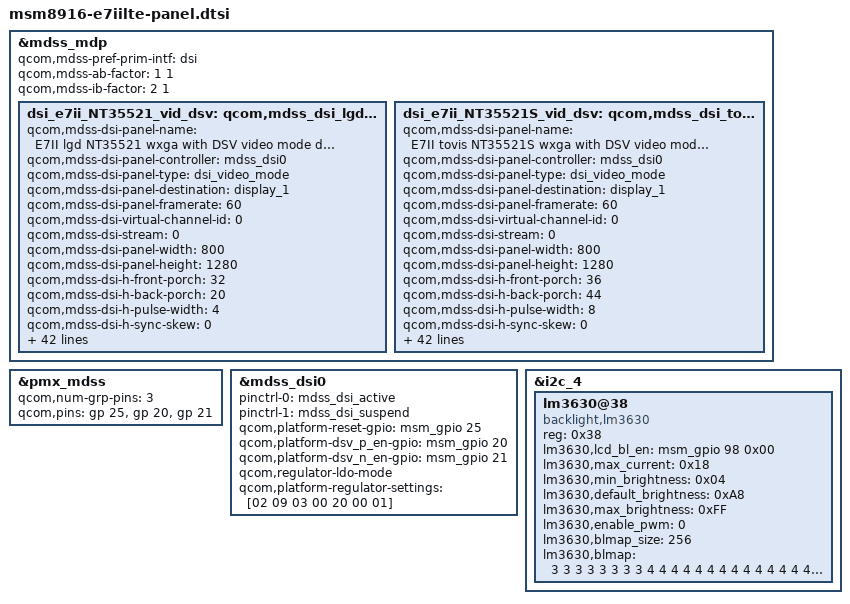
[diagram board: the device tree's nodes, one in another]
/* Copyright (c) 2013, Code Aurora Forum. All rights reserved.
 *
 * This program is free software; you can redistribute it and/or modify
 * it under the terms of the GNU General Public License version 2 and
 * only version 2 as published by the Free Software Foundation.
 *
 * This program is distributed in the hope that it will be useful,
 * but WITHOUT ANY WARRANTY; without even the implied warranty of
 * MERCHANTABILITY or FITNESS FOR A PARTICULAR PURPOSE.  See the
 * GNU General Public License for more details.
 */

&mdss_mdp {
	dsi_e7ii_NT35521_vid_dsv: qcom,mdss_dsi_lgd_nt35521_e7II_wxga_video {
		qcom,mdss-dsi-panel-name = "E7II lgd NT35521 wxga with DSV video mode dsi primary panel";
		qcom,mdss-dsi-panel-controller = <&mdss_dsi0>;
		qcom,mdss-dsi-panel-type = "dsi_video_mode";
		qcom,mdss-dsi-panel-destination = "display_1";
		qcom,mdss-dsi-panel-framerate = <60>;
		qcom,mdss-dsi-virtual-channel-id = <0>;
		qcom,mdss-dsi-stream = <0>;
		qcom,mdss-dsi-panel-width = <800>;
		qcom,mdss-dsi-panel-height = <1280>;
		qcom,mdss-dsi-h-front-porch = <32>;
		qcom,mdss-dsi-h-back-porch = <20>;
		qcom,mdss-dsi-h-pulse-width = <4>;
		qcom,mdss-dsi-h-sync-skew = <0>;
		qcom,mdss-dsi-v-front-porch = <32>;
		qcom,mdss-dsi-v-back-porch = <20>;
		qcom,mdss-dsi-v-pulse-width = <4>;
		qcom,mdss-dsi-h-left-border = <0>;
		qcom,mdss-dsi-h-right-border = <0>;
		qcom,mdss-dsi-v-top-border = <0>;
		qcom,mdss-dsi-v-bottom-border = <0>;
		qcom,mdss-pan-physical-width-dimension = < 94 >;
		qcom,mdss-pan-physical-height-dimension = < 150 >;
		qcom,mdss-dsi-bpp = <24>;
		qcom,mdss-dsi-color-order = "rgb_swap_rgb";
		qcom,mdss-dsi-underflow-color = <0x0>;
		qcom,mdss-dsi-border-color = <0>;
		qcom,mdss-dsi-lp11-init;
		qcom,cont-splash-enabled;
		qcom,mdss-dsi-on-command = [
		39 01 00 00 00 00 05 FF AA 55 A5 80
		15 01 00 00 00 00 02 6F 02
		15 01 00 00 00 00 02 F7 47
		15 01 00 00 00 00 02 6F 17
		15 01 00 00 00 00 02 F4 60
		39 01 00 00 00 00 06 F0 55 AA 52 08 00
		39 01 00 00 00 00 03 B1 28 01
		15 01 00 00 00 00 02 B5 C8
		15 01 00 00 00 00 02 B6 0A
		39 01 00 00 00 00 05 B8 01 02 0C 02
		39 01 00 00 00 00 03 BB 33 33
		39 01 00 00 00 00 03 BC 05 05
		39 01 00 00 00 00 06 BD 02 67 20 20 00
		15 01 00 00 00 00 02 D0 00
		15 01 00 00 00 00 02 C8 83
		39 01 00 00 00 00 11 CC 40 36 87 00 00 00 00 00 00 00 00 00 40 08 A5 05
		39 01 00 00 00 00 11 D1 00 06 0A 0E 12 16 22 28 22 20 16 14 12 0E 08 00
		39 01 00 00 00 00 0D D7 26 28 25 23 23 00 00 00 00 00 00 00
		39 01 00 00 00 00 0E D8 00 00 00 00 00 00 00 00 00 00 23 25 00
		39 01 00 00 00 00 06 F0 55 AA 52 08 01
		39 01 00 00 00 00 03 B3 28 28
		39 01 00 00 00 00 03 B4 0F 0F
		39 01 00 00 00 00 03 B9 34 34
		39 01 00 00 00 00 03 BA 14 14
		39 01 00 00 00 00 03 BC 50 00
		39 01 00 00 00 00 03 BD 50 00
		15 01 00 00 00 00 02 C1 01
		15 01 00 00 00 00 02 CA 80
		39 01 00 00 00 00 03 CB 92 F4
		39 01 00 00 00 00 04 CD 15 03 01
		39 01 00 00 00 00 04 CF 00 50 50
		39 01 00 00 00 00 03 D0 50 50
		39 01 00 00 00 00 03 D1 50 50
		15 01 00 00 00 00 02 D2 39
		15 01 00 00 00 00 02 D3 39
		39 01 00 00 00 00 06 F0 55 AA 52 08 02
		15 01 00 00 00 00 02 EE 01
		39 01 00 00 00 00 11 B0 00 00 00 1E 00 48 00 68 00 81 00 AA 00 CA 00 FE
		39 01 00 00 00 00 11 B1 01 28 01 69 01 9C 01 EB 02 28 02 2A 02 61 02 9B
		39 01 00 00 00 00 11 B2 02 C2 02 F4 03 16 03 42 03 63 03 86 03 9F 03 BB
		39 01 00 00 00 00 05 B3 03 E6 03 FF
		39 01 00 00 00 00 06 F0 55 AA 52 08 03
		39 01 00 00 00 00 03 B0 22 00
		39 01 00 00 00 00 03 B1 22 00
		39 01 00 00 00 00 06 B2 05 00 B0 00 00
		39 01 00 00 00 00 06 B3 05 00 B0 00 00
		39 01 00 00 00 00 06 B4 05 00 B0 00 00
		39 01 00 00 00 00 06 B5 05 00 B0 00 00
		39 01 00 00 00 00 06 BA 53 00 B0 00 00
		39 01 00 00 00 00 06 BB 53 00 B0 00 00
		39 01 00 00 00 00 06 BC 53 00 B0 00 00
		39 01 00 00 00 00 06 BD 53 00 B0 00 00
		39 01 00 00 00 00 05 C0 00 60 00 00
		39 01 00 00 00 00 05 C1 00 00 60 00
		39 01 00 00 00 00 05 C2 00 00 34 00
		39 01 00 00 00 00 05 C3 00 00 34 00
		15 01 00 00 00 00 02 C4 60
		15 01 00 00 00 00 02 C5 C0
		15 01 00 00 00 00 02 C6 00
		15 01 00 00 00 00 02 C7 00
		39 01 00 00 00 00 06 F0 55 AA 52 08 05
		39 01 00 00 00 00 03 B0 17 06
		39 01 00 00 00 00 03 B1 17 06
		39 01 00 00 00 00 03 B2 17 06
		39 01 00 00 00 00 03 B3 17 06
		39 01 00 00 00 00 03 B4 17 06
		39 01 00 00 00 00 03 B5 17 06
		39 01 00 00 00 00 03 B6 17 06
		39 01 00 00 00 00 03 B7 17 06
		15 01 00 00 00 00 02 B8 00
		39 01 00 00 00 00 03 B9 00 03
		39 01 00 00 00 00 03 BA 00 00
		39 01 00 00 00 00 03 BB 02 03
		39 01 00 00 00 00 03 BC 02 03
		39 01 00 00 00 00 06 BD 03 03 00 03 03
		15 01 00 00 00 00 02 C0 0B
		15 01 00 00 00 00 02 C1 09
		15 01 00 00 00 00 02 C2 A6
		15 01 00 00 00 00 02 C3 05
		15 01 00 00 00 00 02 C4 00
		15 01 00 00 00 00 02 C5 02
		15 01 00 00 00 00 02 C6 22
		15 01 00 00 00 00 02 C7 03
		39 01 00 00 00 00 03 C8 07 20
		39 01 00 00 00 00 03 C9 03 20
		39 01 00 00 00 00 03 CA 01 60
		39 01 00 00 00 00 03 CB 01 60
		39 01 00 00 00 00 04 CC 00 00 78
		39 01 00 00 00 00 04 CD 00 00 78
		39 01 00 00 00 00 04 CE 00 00 02
		39 01 00 00 00 00 04 CF 00 00 02
		39 01 00 00 00 00 06 D1 00 05 01 07 10
		39 01 00 00 00 00 06 D2 10 05 05 03 10
		39 01 00 00 00 00 06 D3 20 00 43 07 10
		39 01 00 00 00 00 06 D4 30 00 43 07 10
		39 01 00 00 00 00 08 D0 00 00 00 00 00 00 00
		39 01 00 00 00 00 0C D5 00 00 00 00 00 00 00 00 00 00 00
		39 01 00 00 00 00 0C D6 00 00 00 00 00 00 00 00 00 00 00
		39 01 00 00 00 00 0C D7 00 00 00 00 00 00 00 00 00 00 00
		39 01 00 00 00 00 06 D8 00 00 00 00 00
		15 01 00 00 00 00 02 E5 06
		15 01 00 00 00 00 02 E6 06
		15 01 00 00 00 00 02 E7 00
		15 01 00 00 00 00 02 E8 06
		15 01 00 00 00 00 02 E9 06
		15 01 00 00 00 00 02 EA 06
		15 01 00 00 00 00 02 EB 00
		15 01 00 00 00 00 02 EC 00
		15 01 00 00 00 00 02 ED 30
		39 01 00 00 00 00 06 F0 55 AA 52 08 06
		39 01 00 00 00 00 03 B0 34 34
		39 01 00 00 00 00 03 B1 34 34
		39 01 00 00 00 00 03 B2 2D 2E
		39 01 00 00 00 00 03 B3 34 34
		39 01 00 00 00 00 03 B4 29 2A
		39 01 00 00 00 00 03 B5 13 11
		39 01 00 00 00 00 03 B6 19 17
		39 01 00 00 00 00 03 B7 01 03
		39 01 00 00 00 00 03 B8 34 31
		39 01 00 00 00 00 03 B9 31 31
		39 01 00 00 00 00 03 BA 31 31
		39 01 00 00 00 00 03 BB 31 34
		39 01 00 00 00 00 03 BC 02 00
		39 01 00 00 00 00 03 BD 16 18
		39 01 00 00 00 00 03 BE 10 12
		39 01 00 00 00 00 03 BF 2A 29
		39 01 00 00 00 00 03 C0 34 34
		39 01 00 00 00 00 03 C1 2E 2D
		39 01 00 00 00 00 03 C2 34 34
		39 01 00 00 00 00 03 C3 34 34
		39 01 00 00 00 00 06 D8 00 00 00 00 00
		39 01 00 00 00 00 06 D9 00 00 00 00 00
		39 01 00 00 00 00 05 FF AA 55 A5 00
		39 01 00 00 00 00 06 F0 55 AA 52 00 00
		05 01 00 00 78 00 02 11 00
		15 01 00 00 00 00 02 51 FF
		15 01 00 00 00 00 02 53 24
		15 01 00 00 00 00 02 55 80
		05 01 00 00 00 00 02 29 00];
		qcom,mdss-dsi-off-command = [
		05 01 00 00 32 00 02 28 00
		05 01 00 00 78 00 02 10 00
		];
		qcom,mdss-dsi-on-command-state = "dsi_lp_mode";
		qcom,mdss-dsi-off-command-state = "dsi_hs_mode";
		qcom,mdss-dsi-h-sync-pulse = <0>;
		qcom,mdss-dsi-traffic-mode = "non_burst_sync_event";
		qcom,mdss-dsi-lane-map = "lane_map_0123";
		qcom,mdss-dsi-bllp-eof-power-mode;
		qcom,mdss-dsi-bllp-power-mode;
		qcom,mdss-dsi-lane-0-state;
		qcom,mdss-dsi-lane-1-state;
		qcom,mdss-dsi-lane-2-state;
		qcom,mdss-dsi-lane-3-state;
		qcom,mdss-dsi-panel-timings = [7B 1A 10 00 3E 42 14 1C 15 03 04 00];
		qcom,mdss-dsi-t-clk-post = <0x04>;
		qcom,mdss-dsi-t-clk-pre = <0x1A>;
		qcom,mdss-dsi-bl-min-level = <1>;
		qcom,mdss-dsi-bl-max-level = <255>;
		qcom,mdss-dsi-dma-trigger = "trigger_sw";
		qcom,mdss-dsi-mdp-trigger = "none";
		qcom,mdss-dsi-bl-pmic-control-type = "bl_ctrl_wled";
		qcom,mdss-dsi-reset-sequence = <1 1>, <0 1>, <1 150>;
	};

	dsi_e7ii_NT35521S_vid_dsv: qcom,mdss_dsi_tovis_nt35521s_e7II_wxga_video {
		qcom,mdss-dsi-panel-name = "E7II tovis NT35521S wxga with DSV video mode dsi secondary panel";
		qcom,mdss-dsi-panel-controller = <&mdss_dsi0>;
		qcom,mdss-dsi-panel-type = "dsi_video_mode";
		qcom,mdss-dsi-panel-destination = "display_1";
		qcom,mdss-dsi-panel-framerate = <60>;
		qcom,mdss-dsi-virtual-channel-id = <0>;
		qcom,mdss-dsi-stream = <0>;
		qcom,mdss-dsi-panel-width = <800>;
		qcom,mdss-dsi-panel-height = <1280>;
		qcom,mdss-dsi-h-front-porch = <36>;
		qcom,mdss-dsi-h-back-porch = <44>;
		qcom,mdss-dsi-h-pulse-width = <8>;
		qcom,mdss-dsi-h-sync-skew = <0>;
		qcom,mdss-dsi-v-front-porch = <20>;
		qcom,mdss-dsi-v-back-porch = <36>;
		qcom,mdss-dsi-v-pulse-width = <2>;
		qcom,mdss-dsi-h-left-border = <0>;
		qcom,mdss-dsi-h-right-border = <0>;
		qcom,mdss-dsi-v-top-border = <0>;
		qcom,mdss-dsi-v-bottom-border = <0>;
		qcom,mdss-pan-physical-width-dimension = < 94 >;
		qcom,mdss-pan-physical-height-dimension = < 150 >;
		qcom,mdss-dsi-bpp = <24>;
		qcom,mdss-dsi-color-order = "rgb_swap_rgb";
		qcom,mdss-dsi-underflow-color = <0x0>;
		qcom,mdss-dsi-border-color = <0>;
		qcom,mdss-dsi-lp11-init;
		qcom,cont-splash-enabled;
		qcom,mdss-dsi-on-command = [
		39 01 00 00 00 00 06 F0 55 AA 52 08 00
		39 01 00 00 00 00 03 B1 68 01
		15 01 00 00 00 00 02 B6 01
		39 01 00 00 00 00 05 B8 01 02 02 02
		39 01 00 00 00 00 03 BB CC CC
		39 01 00 00 00 00 03 BC 05 05
		39 01 00 00 00 00 06 BD 01 A0 0C 08 01
		39 01 00 00 00 00 06 F0 55 AA 52 08 01
		39 01 00 00 00 00 03 B3 28 28
		39 01 00 00 00 00 03 B4 0F 0F
		39 01 00 00 00 00 03 B5 03 03
		39 01 00 00 00 00 03 B9 34 34
		39 01 00 00 00 00 03 BA 15 15
		39 01 00 00 00 00 03 BC 78 00
		39 01 00 00 00 00 03 BD 78 00
		15 01 00 00 00 00 02 CA 00
		39 01 00 00 00 00 06 F0 55 AA 52 08 02
		15 01 00 00 00 00 02 EE 02
		39 01 00 00 00 00 11 B0 00 64 00 7D 00 AE 00 C7 00 DF 01 04 01 23 01 52
		39 01 00 00 00 00 11 B1 01 74 01 B0 01 DF 02 27 02 62 02 64 02 97 02 CF
		39 01 00 00 00 00 11 B2 02 F0 03 1F 03 3E 03 63 03 7F 03 9F 03 B9 03 D4
		39 01 00 00 00 00 05 B3 03 EC 03 F0
		39 01 00 00 00 00 11 BC 00 64 00 7D 00 AE 00 C7 00 DF 01 04 01 23 01 52
		39 01 00 00 00 00 11 BD 01 74 01 B0 01 DF 02 27 02 62 02 64 02 97 02 CF
		39 01 00 00 00 00 11 BE 02 F0 03 1F 03 3E 03 63 03 7F 03 9F 03 B9 03 D4
		39 01 00 00 00 00 05 BF 03 EC 03 F0
		39 01 00 00 00 00 06 F0 55 AA 52 08 03
		39 01 00 00 00 00 03 B0 20 00
		39 01 00 00 00 00 03 B1 00 00
		39 01 00 00 00 00 06 B2 05 00 00 00 90
		39 01 00 00 00 00 06 B3 05 00 00 00 90
		39 01 00 00 00 00 06 B4 05 00 00 00 90
		39 01 00 00 00 00 06 B5 05 00 00 00 90
		39 01 00 00 00 00 06 B6 05 00 00 00 90
		39 01 00 00 00 00 06 B7 05 00 00 00 90
		39 01 00 00 00 00 06 B8 05 00 00 00 90
		39 01 00 00 00 00 06 B9 05 00 00 00 90
		39 01 00 00 00 00 06 BA 44 00 00 01 00
		39 01 00 00 00 00 06 BB 44 00 00 01 00
		39 01 00 00 00 00 06 BC 44 00 00 01 00
		39 01 00 00 00 00 06 BD 44 00 00 01 00
		15 01 00 00 00 00 02 C4 60
		15 01 00 00 00 00 02 C5 40
		15 01 00 00 00 00 02 C6 60
		15 01 00 00 00 00 02 C7 40
		39 01 00 00 00 00 06 F0 55 AA 52 08 05
		39 01 00 00 00 00 03 B0 17 06
		15 01 00 00 00 00 02 B8 00
		39 01 00 00 00 00 06 BD 03 03 01 00 03
		39 01 00 00 00 00 03 B1 17 06
		39 01 00 00 00 00 03 B9 00 03
		39 01 00 00 00 00 03 B2 17 06
		39 01 00 00 00 00 03 BA 00 00
		39 01 00 00 00 00 03 B3 17 06
		39 01 00 00 00 00 03 BB 00 00
		39 01 00 00 00 00 03 B4 17 06
		39 01 00 00 00 00 03 B5 17 06
		39 01 00 00 00 00 03 B6 17 06
		39 01 00 00 00 00 03 B7 17 06
		39 01 00 00 00 00 03 BC 00 03
		15 01 00 00 00 00 02 C0 0B
		15 01 00 00 00 00 02 C1 09
		15 01 00 00 00 00 02 C2 0B
		15 01 00 00 00 00 02 C3 09
		15 01 00 00 00 00 02 C4 10
		15 01 00 00 00 00 02 C5 10
		15 01 00 00 00 00 02 C6 10
		15 01 00 00 00 00 02 C7 10
		39 01 00 00 00 00 03 C8 07 20
		39 01 00 00 00 00 03 C9 03 20
		39 01 00 00 00 00 03 CA 07 00
		39 01 00 00 00 00 03 CB 03 00
		39 01 00 00 00 00 08 D0 00 00 00 00 00 00 00
		39 01 00 00 00 00 06 D1 00 05 00 07 10
		39 01 00 00 00 00 06 D2 00 05 04 07 10
		39 01 00 00 00 00 06 D3 00 00 0A 07 10
		39 01 00 00 00 00 06 D4 00 00 0A 07 10
		39 01 00 00 00 00 0C D5 00 00 00 00 00 00 00 00 00 00 00
		39 01 00 00 00 00 0C D6 00 00 00 00 00 00 00 00 00 00 00
		39 01 00 00 00 00 0C D7 00 00 00 00 00 00 00 00 00 00 00
		39 01 00 00 00 00 06 D8 00 00 00 00 00
		15 01 00 00 00 00 02 E5 06
		15 01 00 00 00 00 02 E6 06
		15 01 00 00 00 00 02 E7 06
		15 01 00 00 00 00 02 E8 06
		15 01 00 00 00 00 02 E9 06
		15 01 00 00 00 00 02 EA 06
		15 01 00 00 00 00 02 EB 06
		15 01 00 00 00 00 02 EC 06
		15 01 00 00 00 00 02 ED 30
		39 01 00 00 00 00 06 F0 55 AA 52 08 06
		39 01 00 00 00 00 03 B0 31 2E
		39 01 00 00 00 00 03 B1 2D 12
		39 01 00 00 00 00 03 B2 10 18
		39 01 00 00 00 00 03 B3 16 00
		39 01 00 00 00 00 03 B4 02 31
		39 01 00 00 00 00 03 B5 31 08
		39 01 00 00 00 00 03 B6 31 31
		39 01 00 00 00 00 03 B7 31 31
		39 01 00 00 00 00 03 B8 31 31
		39 01 00 00 00 00 03 B9 31 31
		39 01 00 00 00 00 03 BA 31 31
		39 01 00 00 00 00 03 BB 31 31
		39 01 00 00 00 00 03 BC 31 31
		39 01 00 00 00 00 03 BD 31 31
		39 01 00 00 00 00 03 BE 09 31
		39 01 00 00 00 00 03 BF 31 03
		39 01 00 00 00 00 03 C0 01 17
		39 01 00 00 00 00 03 C1 19 11
		39 01 00 00 00 00 03 C2 13 2D
		39 01 00 00 00 00 03 C3 2E 31
		39 01 00 00 00 00 03 E5 31 31
		39 01 00 00 00 00 03 C4 31 2D
		39 01 00 00 00 00 03 C5 2E 17
		39 01 00 00 00 00 03 C6 19 11
		39 01 00 00 00 00 03 C7 13 03
		39 01 00 00 00 00 03 C8 01 31
		39 01 00 00 00 00 03 C9 31 09
		39 01 00 00 00 00 03 CA 31 31
		39 01 00 00 00 00 03 CB 31 31
		39 01 00 00 00 00 03 CC 31 31
		39 01 00 00 00 00 03 CD 31 31
		39 01 00 00 00 00 03 CE 31 31
		39 01 00 00 00 00 03 CF 31 31
		39 01 00 00 00 00 03 D0 31 31
		39 01 00 00 00 00 03 D1 31 31
		39 01 00 00 00 00 03 D2 08 31
		39 01 00 00 00 00 03 D3 31 00
		39 01 00 00 00 00 03 D4 02 12
		39 01 00 00 00 00 03 D5 10 18
		39 01 00 00 00 00 03 D6 16 2E
		39 01 00 00 00 00 03 D7 2D 31
		39 01 00 00 00 00 06 D8 00 00 00 00 00
		39 01 00 00 00 00 06 D9 00 00 00 00 00
		15 01 00 00 00 00 02 E7 00
		15 01 00 00 00 00 02 51 FF
		15 01 00 00 00 00 02 53 24
		15 01 00 00 00 00 02 55 00
		05 01 00 00 78 00 02 11 00
		05 01 00 00 00 00 02 29 00];
		qcom,mdss-dsi-off-command = [
		05 01 00 00 32 00 02 28 00
		05 01 00 00 78 00 02 10 00
		];
		qcom,mdss-dsi-on-command-state = "dsi_lp_mode";
		qcom,mdss-dsi-off-command-state = "dsi_hs_mode";
		qcom,mdss-dsi-h-sync-pulse = <0>;
		qcom,mdss-dsi-traffic-mode = "non_burst_sync_event";
		qcom,mdss-dsi-lane-map = "lane_map_0123";
		qcom,mdss-dsi-bllp-eof-power-mode;
		qcom,mdss-dsi-bllp-power-mode;
		qcom,mdss-dsi-lane-0-state;
		qcom,mdss-dsi-lane-1-state;
		qcom,mdss-dsi-lane-2-state;
		qcom,mdss-dsi-lane-3-state;
		qcom,mdss-dsi-panel-timings = [7A 1A 12 00 3E 42 16 1E 14 03 04 00];
		qcom,mdss-dsi-t-clk-post = <0x04>;
		qcom,mdss-dsi-t-clk-pre = <0x1A>;
		qcom,mdss-dsi-bl-min-level = <1>;
		qcom,mdss-dsi-bl-max-level = <255>;
		qcom,mdss-dsi-dma-trigger = "trigger_sw";
		qcom,mdss-dsi-mdp-trigger = "none";
		qcom,mdss-dsi-bl-pmic-control-type = "bl_ctrl_wled";
		qcom,mdss-dsi-reset-sequence = <1 1>, <0 10>, <1 120>;
	};
};

&mdss_mdp {
       qcom,mdss-pref-prim-intf = "dsi";
       qcom,mdss-ab-factor = <1 1>;
       qcom,mdss-ib-factor = <2 1>;
};

&pmx_mdss {
       qcom,num-grp-pins = <3>;
       qcom,pins = <&gp 25>, <&gp 20>, <&gp 21>;
};

&mdss_dsi0 {
       pinctrl-names = "mdss_default", "mdss_sleep";
       pinctrl-0 = <&mdss_dsi_active>;
       pinctrl-1 = <&mdss_dsi_suspend>;

       qcom,platform-reset-gpio = <&msm_gpio 25 0>;
       qcom,platform-dsv_p_en-gpio = <&msm_gpio 20 0>;
       qcom,platform-dsv_n_en-gpio = <&msm_gpio 21 0>;
       qcom,regulator-ldo-mode;
       qcom,platform-regulator-settings = [02 09 03 00 20 00 01];
};

&i2c_4 {

        lm3630@38 {
                compatible = "backlight,lm3630";
                status = "ok";
                reg = <0x38>;
                lm3630,lcd_bl_en = <&msm_gpio 98 0x00>;
                lm3630,max_current = <0x18>;
                lm3630,min_brightness = <0x04>;
                lm3630,default_brightness = <0xA8>;
                lm3630,max_brightness = <0xFF>;
                lm3630,enable_pwm = <0>;
                lm3630,blmap_size = <256>;
                lm3630,blmap = <
					3 3 3 3 3 3 3 3 4 4 4 4 4 4 4
					4 4 4 4 4 4 4 5 5 5 5 5 5 5 5
					5 5 5 5 5 6 6 6 6 6 6 6 6 7 7
					7 8 8 8 9 9 9 9 9 10 10 10 11 11 11
					12 12 12 12 13 13 13 13 14 14 15 15 15 16 16
					17 17 17 18 18 18 19 19 20 21 22 22 23 24 24
					25 25 26 26 27 28 28 29 29 30 30 31 31 32 32
					33 34 35 35 36 36 37 38 39 39 40 41 41 42 43
					44 45 45 46 47 48 49 50 51 52 53 54 55 56 57
					58 59 60 61 62 63 64 65 66 67 68 69 70 71 72
					73 74 75 76 76 77 78 80 81 82 83 85 86 87 88
					89 90 91 93 95 96 97 99 100 102 103 104 106 107 108
					109 110 112 114 115 117 119 121 123 125 127 128 129 130 132
					133 135 136 138 139 140 142 144 146 148 150 151 153 154 156
					157 158 159 161 163 164 165 167 168 170 173 175 177 180 184
					186 188 191 194 197 199 201 203 205 207 209 211 213 215 217
					219 221 223 225 227 228 230 232 235 238 240 243 246 249 252
					255>;
        };
};

